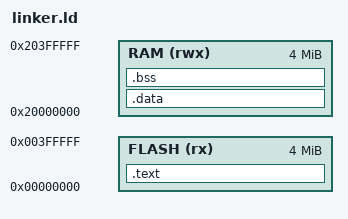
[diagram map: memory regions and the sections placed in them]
MEMORY
{
    FLASH (rx)  : ORIGIN = 0x00000000, LENGTH = 4M
    RAM   (rwx) : ORIGIN = 0x20000000, LENGTH = 4M
}

SECTIONS
{
    .text :
    {
        *(.vectors)
        *(.text*)
        *(.rodata*)
    } > FLASH

    .data :
    {
        *(.data*)
    } > RAM

    .bss :
    {
        *(.bss*)
    } > RAM
}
